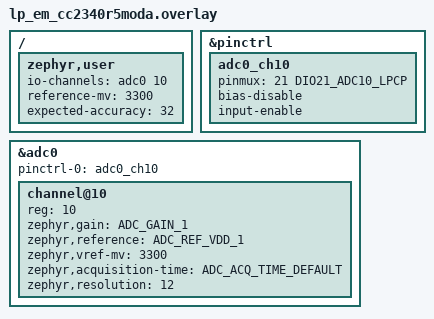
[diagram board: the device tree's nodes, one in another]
/*
 * Copyright (c) 2026 Texas Instruments Incorporated
 *
 * SPDX-License-Identifier: Apache-2.0
 */

/*
 * Requires external hardware connection:
 * This test reads ADC channel 10 (DIO21, jumper P2 pin 2) and
 * expects it to be driven to 3.3V (reference-mv).
 * Connect DIO21 (jumper P2 pin 2) to 3.3V supply.
 *
 */

#include <zephyr/dt-bindings/adc/adc.h>
#include <zephyr/dt-bindings/pinctrl/cc23x0-pinctrl.h>

/ {
	zephyr,user {
		io-channels = <&adc0 10>;
		reference-mv = <3300>;
		expected-accuracy = <32>;
	};
};

&pinctrl {
	/* ADC0 - Channel 10 using DIO21 (ADC10_LPCP) */
	adc0_ch10: adc0_ch10 {
		pinmux = <21 DIO21_ADC10_LPCP>;
		bias-disable;
		input-enable;
	};
};

&adc0 {
	status = "okay";
	pinctrl-0 = <&adc0_ch10>;
	pinctrl-names = "default";
	#address-cells = <1>;
	#size-cells = <0>;

	channel@10 {
		reg = <10>;
		zephyr,gain = "ADC_GAIN_1";
		zephyr,reference = "ADC_REF_VDD_1";
		zephyr,vref-mv = <3300>;
		zephyr,acquisition-time = <ADC_ACQ_TIME_DEFAULT>;
		zephyr,resolution = <12>;
	};
};
